# ESP32-S31 register map
Vendor: ESPRESSIF SYSTEMS (SHANGHAI) CO., LTD.; Series: ESP32 S-Series; File version: 1
CPU: RV32IMAFC r0p0, little endian, no MPU, FPU, 0 interrupt priority bits
Address unit: 32 bits
Registers are 32-bit, read-write, reset 0x0 unless marked. A register's access mark holds for its fields unless they carry their own. Offsets are from the block's base; [hi:lo] are bit positions; {n}, {i} and the like mark numbered series; <NAME> marks a mode.

## USB_OTG_HS (part 3 of 5) — USB_OTG_HS Peripheral
Base 0x20300000
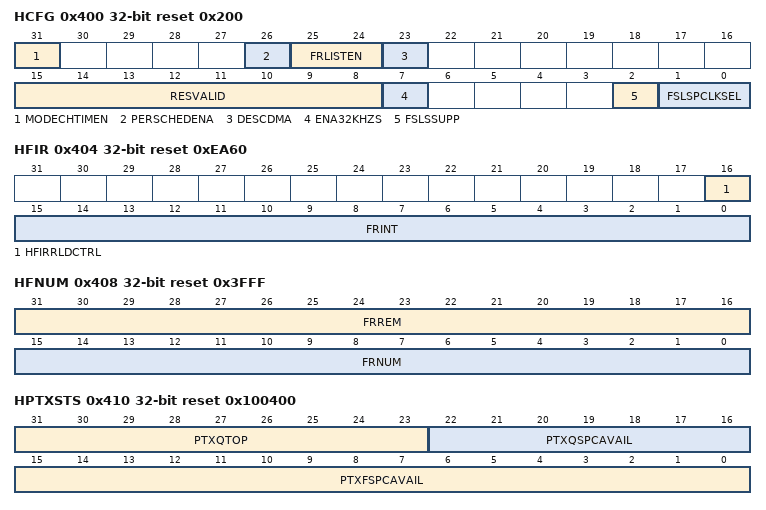
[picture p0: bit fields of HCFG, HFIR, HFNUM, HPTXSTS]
0x400 HCFG reset 0x200 — This register is used to configure the controller in Host mode.
  [31] MODECHTIMEN — Mode Change Ready Timer Enable (ModeChTimEn) This bit is used to enable/disable the Host core to wait 200 PHY clock cycles at the end of Resume to change the opmode signal to the PHY to 00 after Suspend or LPM. - 1'b0 : The Host core waits for either 200 PHY clock cycles or a linestate of SE0 at the end of resume to the change the opmode from 2'b10 to 2'b00 - 1'b1 : The Host core waits only for a linestate of SE0 at the end of resume to change the opmode from 2'b10 to 2'b00.
  [26] PERSCHEDENA — Enable Periodic Scheduling (PerSchedEna): Applicable in host DDMA mode only. Enables periodic scheduling within the core. Initially, the bit is reset. The core does not process any periodic channels. As soon as this bit is set, the core gets ready to start scheduling periodic channels and sets HCFG.PerSchedStat. The setting of HCFG.PerSchedStat indicates the core has enabled periodic scheduling. Once HCFG.PerSchedEna is set, the application is not supposed to again reset the bit unless HCFG.PerSchedStat is set. As soon as this bit is reset, the core gets ready to stop scheduling periodic channels and resets HCFG.PerSchedStat.
  [25:24] FRLISTEN — Frame List Entries(FrListEn) The value in the register specifies the number of entries in the Frame list. This field is valid only in Scatter/Gather DMA mode. - 2'b00: 8 Entries - 2'b01: 16 Entries - 2'b10: 32 Entries - 2'b11: 64 Entries
  [23] DESCDMA — Enable Scatter/gather DMA in Host mode (DescDMA) When the Scatter/Gather DMA option selected during configuration of the RTL, the application can set this bit during initialization to enable the Scatter/Gather DMA operation. Note: This bit must be modified only once after a reset. The following combinations are available for programming: - GAHBCFG.DMAEn=0,HCFG.DescDMA=0 => Slave mode - GAHBCFG.DMAEn=0,HCFG.DescDMA=1 => Invalid - GAHBCFG.DMAEn=1,HCFG.DescDMA=0 => Buffered DMA mode - GAHBCFG.DMAEn=1,HCFG.DescDMA=1 => Scatter/Gather DMA mode
  [15:8] RESVALID — Resume Validation Period (ResValid) This field is effective only when HCFG.Ena32KHzS is set. It controls the resume period when the core resumes from suspend. The core counts for 'ResValid' number of clock cycles to detect a valid resume when this is set.
  [7] ENA32KHZS — Enable 32 KHz Suspend mode (Ena32KHzS) This bit can be set only in FS PHY interface is selected. Else, this bit needs to be set to zero. When FS PHY interface is chosen and this bit is set, the core expects that the PHY clock during Suspend is switched from 48 MHz to 32 KHz.
  [2] FSLSSUPP — FS- and LS-Only Support (FSLSSupp) The application uses this bit to control the core's enumeration speed. Using this bit, the application can make the core enumerate as a FS host, even If the connected device supports HS traffic. Do not make changes to this field after initial programming. - 1'b0: HS/FS/LS, based on the maximum speed supported by the connected device - 1'b1: FS/LS-only, even If the connected device can support HS
  [1:0] FSLSPCLKSEL — FS/LS PHY Clock Select (FSLSPclkSel) When the core is in FS Host mode - 2'b00: PHY clock is running at 30/60 MHz - 2'b01: PHY clock is running at 48 MHz - Others: Reserved When the core is in LS Host mode - 2'b00: PHY clock is running at 30/60 MHz. When the UTMI+/ULPI PHY Low Power mode is not selected, use 30/60 MHz. - 2'b01: PHY clock is running at 48 MHz. When the UTMI+ PHY Low Power mode is selected, use 48MHz If the PHY supplies a 48 MHz clock during LS mode. - 2'b10: PHY clock is running at 6 MHz. In USB 1.1 FS mode, use 6 MHz when the UTMI+ PHY Low Power mode is selected and the PHY supplies a 6 MHz clock during LS mode. If you select a 6 MHz clock during LS mode, you must do a soft reset. - 2'b11: Reserved Notes: - When Core in FS mode, the internal and external clocks have the same frequency. - When Core in LS mode, -- If FSLSPclkSel = 2'b00: Internal and external clocks have the same frequency -- If FSLSPclkSel = 2'b10: Internal clock is the divided by eight version of external 48 MHz clock
0x404 HFIR reset 0xEA60 — This register is used to control the interval between two consecutive SOFs.
  [16] HFIRRLDCTRL — Reload Control (HFIRRldCtrl) This bit allows dynamic reloading of the HFIR register during run time. - 1'b0 : The HFIR cannot be reloaded dynamically - 1'b1: the HFIR can be dynamically reloaded during runtime. This bit needs to be programmed during initial configuration and its value must not be changed during runtime.
  [15:0] FRINT — Frame Interval (FrInt) The value that the application programs to this field specifies the interval between two consecutive SOFs (FS) or micro- SOFs (HS) or Keep-Alive tokens (HS). This field contains the number of PHY clocks that constitute the required frame interval. The Default value set in this field is for FS operation when the PHY clock frequency is 60 MHz. The application can write a value to this register only after the Port Enable bit of the Host Port Control and Status register (HPRT.PrtEnaPort) has been Set. If no value is programmed, the core calculates the value based on the PHY clock specified in the FS/LS PHY Clock Select field of the Host Configuration register (HCFG.FSLSPclkSel). Do not change the value of this field after the initial configuration. - 125 us * (PHY clock frequency for HS) - 1 ms * (PHY clock frequency for FS/LS)
0x408 HFNUM ro reset 0x3FFF — This register indicates the current frame number. It also indicates the time remaining (in terms of the number of PHY clocks) in the current (micro)frame. Note: Read the reset value of this register only after the following conditions: - If IDDIG_FILTER is disabled, read only when the PHY clock is stable. - If IDDIG_FILTER is enabled, read only after the filter timer expires.
  [31:16] FRREM — Frame Time Remaining (FrRem) Indicates the amount of time remaining in the current microframe (HS) or Frame (FS/LS), in terms of PHY clocks. This field decrements on each PHY clock. When it reaches zero, this field is reloaded with the value in the Frame Interval register and a new SOF is transmitted on the USB.
  [15:0] FRNUM — Frame Number (FrNum) This field increments when a new SOF is transmitted on the USB, and is reset to 0 when it reaches 16'h3FFF.
0x410 HPTXSTS ro reset 0x100400 — This register contains information about the Periodic Transmit Queue in the Host controller.
  [31:23] PTXQTOP — Top of the Periodic Transmit Request Queue (PTxQTop) This indicates the Entry in the Periodic Tx Request Queue that is currently being processed by the MAC. This register is used for debugging. - Bit [31]: Odd/Even (micro)Frame -- 1'b0: send in even (micro)Frame -- 1'b1: send in odd (micro)Frame - Bits [30:27]: Channel/endpoint number - Bits [26:25]: Type -- 2'b00: IN/OUT -- 2'b01: Zero-length packet -- 2'b10: CSPLIT -- 2'b11: Disable channel command - Bit [24]: Last Periodic Entry for the selected periodic channel/endpoint - Bit [23]: Terminate (last Entry for the selected channel/endpoint)
  [22:16] PTXQSPCAVAIL — Periodic Transmit Request Queue Space Available (PTxQSpcAvail) Indicates the number of free locations available to be written in the Periodic Transmit Request Queue. This queue holds both IN and OUT requests. - 7'h0: Periodic Transmit Request Queue is full - 7'h1: 1 location available - 7'h2: 2 locations available - n: n locations available (0 <= n <= 16) - Others: Reserved
  [15:0] PTXFSPCAVAIL — Periodic Transmit Data FIFO Space Available (PTxFSpcAvail) Indicates the number of free locations available to be written to in the Periodic TxFIFO. Values are in terms of 32-bit words - 16'h0 : Periodic TxFIFO is full - 16'h1 : 1 word available - 16'h2 : 2 words available - 16'hn : n words available (where 0 n 32,768) - 16'h8000 : 32,768 words - Others : Reserved
0x414 HAINT ro — When a significant event occurs on a channel, the Host All Channels Interrupt register interrupts the application using the Host Channels Interrupt bit of the Core Interrupt register (GINTSTS.HChInt). This is shown in the Interrupt Hierarchy figure in the databook. There is one interrupt bit per channel, up to a maximum of 16 bits. Bits in this register are set and cleared when the application sets and clears bits in the corresponding Host Channel-n Interrupt register.
  [15:0] HAINT — Channel Interrupt for channel no.
0x418 HAINTMSK — The Host All Channel Interrupt Mask register works with the Host All Channel Interrupt register to interrupt the application when an event occurs on a channel. There is one interrupt mask bit per channel, up to a maximum of 16 bits.
  [15:0] HAINTMSK — Channel Interrupt Mask (HAINTMsk) One bit per channel: Bit 0 for channel 0, bit 15 for channel 15
0x41C HFLBAddr — This register is present only in case of Scatter/Gather DMA. It is implemented as flops. This register holds the starting address of the Frame list information.
  [31:0] HFLBADDR_HFLBADDR — The starting address of the Frame list. This register is used only for Isochronous and Interrupt Channels.
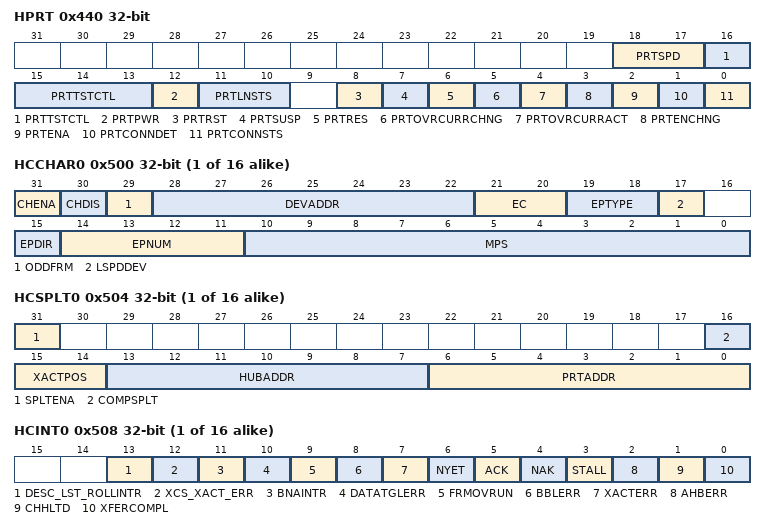
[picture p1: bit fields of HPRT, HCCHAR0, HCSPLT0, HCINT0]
0x440 HPRT access per field — This register is available only in Host mode. Currently, the OTG Host supports only one port. A single register holds USB port-related information such as USB reset, enable, suspend, resume, connect status, and test mode for each port. It is shown in the Interrupt Hierarchy figure in the databook. The R_SS_WC bits in this register can trigger an interrupt to the application through the Host Port Interrupt bit of the Core Interrupt register (GINTSTS.PrtInt). On a Port Interrupt, the application must read this register and clear the bit that caused the interrupt. For the R_SS_WC bits, the application must write a 1 to the bit to clear the interrupt.
  [18:17] PRTSPD ro — Port Speed (PrtSpd) Indicates the speed of the device attached to this port. - 2'b00: High speed - 2'b01: Full speed - 2'b10: Low speed - 2'b11: Reserved
  [16:13] PRTTSTCTL rw — Port Test Control (PrtTstCtl) The application writes a nonzero value to this field to put the port into a Test mode, and the corresponding pattern is signaled on the port. - 4'b0000: Test mode disabled - 4'b0001: Test_J mode - 4'b0010: Test_K mode - 4'b0011: Test_SE0_NAK mode - 4'b0100: Test_Packet mode - 4'b0101: Test_Force_Enable - Others: Reserved To move the DWC_otg controller to test mode, you must set this field. Complete the following steps to move the DWC_otg core to test mode: - 1. Power on the core. - 2. Load the DWC_otg driver. - 3. Connect an HS device and enumerate to HS mode. - 4. Access the HPRT register to send test packets. - 5. Remove the device and connect to fixture (OPT) port. The DWC_otg host core continues sending out test packets. - 6. Test the eye diagram.
  [12] PRTPWR rw — Port Power (PrtPwr) The application uses this field to control power to this port (write 1'b1 to set to 1'b1 and write 1'b0 to set to 1'b0), and the core can clear this bit on an over current condition. - 1'b0: Power off - 1'b1: Power on Note: This bit is interface independent. The application needs to program this bit for all interfaces as described in the host programming flow in the Programming Guide.
  [11:10] PRTLNSTS ro — Port Line Status (PrtLnSts) Indicates the current logic level USB data lines - Bit [10]: Logic level of D+ - Bit [11]: Logic level of D-
  [8] PRTRST rw — Port Reset (PrtRst) When the application sets this bit, a reset sequence is started on this port. The application must time the reset period and clear this bit after the reset sequence is complete. - 1'b0: Port not in reset - 1'b1: Port in reset The application must leave this bit set for at least a minimum duration mentioned below to start a reset on the port. The application can leave it set for another 10 ms in addition to the required minimum duration, before clearing the bit, even though there is no maximum limit Set by the USB standard.This bit is cleared by the core even if there is no device connected to the Host. - High speed: 50 ms - Full speed/Low speed: 10 ms
  [7] PRTSUSP rw — Port Suspend (PrtSusp) The application sets this bit to put this port in Suspend mode. The core only stops sending SOFs when this is Set. To stop the PHY clock, the application must Set the Port Clock Stop bit, which asserts the suspend input pin of the PHY. The read value of this bit reflects the current suspend status of the port. This bit is cleared by the core after a remote wakeup signal is detected or the application sets the Port Reset bit or Port Resume bit in this register or the Resume/Remote Wakeup Detected Interrupt bit or Disconnect Detected Interrupt bit in the Core Interrupt register (GINTSTS.WkUpInt or GINTSTS.DisconnInt, respectively).This bit is cleared by the core even if there is no device connected to the Host. - 1'b0: Port not in Suspend mode - 1'b1: Port in Suspend mode
  [6] PRTRES rw — Port Resume (PrtRes) The application sets this bit to drive resume signaling on the port. The core continues to drive the resume signal until the application clears this bit. If the core detects a USB remote wakeup sequence, as indicated by the Port Resume/Remote Wakeup Detected Interrupt bit of the Core Interrupt register (GINTSTS.WkUpInt), the core starts driving resume signaling without application intervention and clears this bit when it detects a disconnect condition. The read value of this bit indicates whether the core is currently driving resume signaling. - 1'b0: No resume driven - 1'b1: Resume driven When LPM is enabled, In L1 state the behavior of this bit is as follows: The application sets this bit to drive resume signaling on the port. The core continues to drive the resume signal until a pre-determined time specified in GLPMCFG.HIRD_Thres[3:0] field. If the core detects a USB remote wakeup sequence, as indicated by the Port L1Resume/Remote L1Wakeup Detected Interrupt bit of the Core Interrupt register (GINTSTS.L1WkUpInt), the core starts driving resume signaling without application intervention and clears this bit at the end of resume.This bit can be set by both core or application and also cleared by core or application. This bit is cleared by the core even if there is no device connected to the Host.
  [5] PRTOVRCURRCHNG rw — Port Overcurrent Change (PrtOvrCurrChng) The core sets this bit when the status of the Port Overcurrent Active bit (bit 4) in this register changes.This bit can be set only by the core and the application must write 1 to clear it
  [4] PRTOVRCURRACT ro — Port Overcurrent Active (PrtOvrCurrAct) Indicates the overcurrent condition of the port. - 1'b0: No overcurrent condition - 1'b1: Overcurrent condition
  [3] PRTENCHNG rw — Port Enable/Disable Change (PrtEnChng) The core sets this bit when the status of the Port Enable bit [2] of this register changes.This bit can be set only by the core and the application must write 1 to clear it.
  [2] PRTENA rw — Port Enable (PrtEna) A port is enabled only by the core after a reset sequence, and is disabled by an overcurrent condition, a disconnect condition, or by the application clearing this bit. The application cannot Set this bit by a register write. It can only clear it to disable the port by writing 1. This bit does not trigger any interrupt to the application. - 1'b0: Port disabled - 1'b1: Port enabled
  [1] PRTCONNDET rw — Port Connect Detected (PrtConnDet) The core sets this bit when a device connection is detected to trigger an interrupt to the application using the Host Port Interrupt bit of the Core Interrupt register (GINTSTS.PrtInt).This bit can be set only by the core and the application must write 1 to clear it.The application must write a 1 to this bit to clear the interrupt.
  [0] PRTCONNSTS ro — Port Connect Status (PrtConnSts) - 0: No device is attached to the port. - 1: A device is attached to the port.
{0x500+0x20*i} HCCHAR{i} (i=0..15) — This register contains the characteristics of the Host Channel.
  [31] CHENA — Channel Enable (ChEna) When Scatter/Gather mode is enabled - 1'b0: Indicates that the descriptor structure is not yet ready. - 1'b1: Indicates that the descriptor structure and data buffer with data is setup and this channel can access the descriptor. When Scatter/Gather mode is disabled This field is set by the application and cleared by the OTG host. - 1'b0: Channel disabled - 1'b1: Channel enabled
  [30] CHDIS — Channel Disable (ChDis) The application sets this bit to stop transmitting/receiving data on a channel, even before the transfer for that channel is complete. The application must wait for the Channel Disabled interrupt before treating the channel as disabled.
  [29] ODDFRM — Odd Frame (OddFrm) This field is set (reset) by the application to indicate that the OTG host must perform a transfer in an odd (micro)Frame. This field is applicable for only periodic (isochronous and interrupt) transactions. - 1'b0: Even (micro)Frame - 1'b1: Odd (micro)Frame
  [28:22] DEVADDR — Device Address (DevAddr) This field selects the specific device serving as the data source or sink.
  [21:20] EC — Multi Count (MC) / Error Count (EC) When the Split Enable bit of the Host Channel-n Split Control register (HCSPLTn.SpltEna) is reset (1'b0), this field indicates to the host the number of transactions that must be executed per microframe for this periodic endpoint. For non periodic transfers, this field is used only in DMA mode, and specifies the number packets to be fetched for this channel before the internal DMA engine changes arbitration. - 2'b00: Reserved This field yields undefined results. - 2'b01: 1 transaction - 2'b10: 2 transactions to be issued for this endpoint per microframe - 2'b11: 3 transactions to be issued for this endpoint per microframe When HCSPLTn.SpltEna is Set (1'b1), this field indicates the number of immediate retries to be performed for a periodic split transactions on transaction errors. This field must be Set to at least 2'b01.
  [19:18] EPTYPE — Endpoint Type (EPType) Indicates the transfer type selected. - 2'b00: Control - 2'b01: Isochronous - 2'b10: Bulk - 2'b11: Interrupt
  [17] LSPDDEV — Low-Speed Device (LSpdDev) This field is Set by the application to indicate that this channel is communicating to a low-speed device. The application must program this bit when a low speed device is connected to the host through an FS HUB. The DWC_otg Host core uses this field to drive the XCVR_SELECT signal to 2'b11 while communicating to the LS Device through the FS hub. Note: In a peer to peer setup, the DWC_otg Host core ignores this bit even if it is set by the application software.
  [15] EPDIR — Endpoint Direction (EPDir) Indicates whether the transaction is IN or OUT. - 1'b0: OUT - 1'b1: IN
  [14:11] EPNUM — Endpoint Number (EPNum) Indicates the endpoint number on the device serving as the data source or sink.
  [10:0] MPS — Maximum Packet Size (MPS) Indicates the maximum packet size of the associated endpoint.
{0x504+0x20*i} HCSPLT{i} (i=0..15) — This register contains the Split characteristics of the Host Channel.
  [31] SPLTENA — Split Enable (SpltEna) The application sets this field to indicate that this channel is enabled to perform split transactions.
  [16] COMPSPLT — Do Complete Split (CompSplt) The application sets this field to request the OTG host to perform a complete split transaction.
  [15:14] XACTPOS — Transaction Position (XactPos) This field is used to determine whether to send all, first, middle, or last payloads with each OUT transaction. - 2'b11: All. This is the entire data payload is of this transaction (which is less than or equal to 188 bytes). - 2'b10: Begin. This is the first data payload of this transaction (which is larger than 188 bytes). - 2'b00: Mid. This is the middle payload of this transaction (which is larger than 188 bytes). - 2'b01: End. This is the last payload of this transaction (which is larger than 188 bytes).
  [13:7] HUBADDR — Hub Address (HubAddr) This field holds the device address of the transaction translator's hub.
  [6:0] PRTADDR — Port Address (PrtAddr) This field is the port number of the recipient transaction translator.
{0x508+0x20*i} HCINT{i} (i=0..15) — This register indicates the status of a channel with respect to USB- and AHB-related events. It is shown in the Interrupt Hierarchy figure in the databook. The application must read this register when the Host Channels Interrupt bit of the Core Interrupt register (GINTSTS.HChInt) is set. Before the application can read this register, it must first read the Host All Channels Interrupt (HAINT) register to get the exact channel number for the Host Channel-n Interrupt register. The application must clear the appropriate bit in this register to clear the corresponding bits in the HAINT and GINTSTS registers.
  [13] DESC_LST_ROLLINTR — Descriptor rollover interrupt (DESC_LST_ROLLIntr) This bit is valid only when Scatter/Gather DMA mode is enabled. The core sets this bit when the corresponding channel's descriptor list rolls over. For non Scatter/Gather DMA mode, this bit is reserved.
  [12] XCS_XACT_ERR — Excessive Transaction Error (XCS_XACT_ERR) This bit is valid only when Scatter/Gather DMA mode is enabled. The core sets this bit when 3 consecutive transaction errors occurred on the USB bus. XCS_XACT_ERR is not generated for Isochronous channels. For non Scatter/Gather DMA mode, this bit is reserved.
  [11] BNAINTR — BNA (Buffer Not Available) Interrupt (BNAIntr) This bit is valid only when Scatter/Gather DMA mode is enabled. The core generates this interrupt when the descriptor accessed is not ready for the Core to process. BNA is not generated for Isochronous channels. For non Scatter/Gather DMA mode, this bit is reserved.
  [10] DATATGLERR — Data Toggle Error (DataTglErr).This bit can be set only by the core and the application must write 1 to clear it.In Scatter/Gather DMA mode, the interrupt due to this bit is masked in the core.
  [9] FRMOVRUN — Frame Overrun (FrmOvrun). In Scatter/Gather DMA mode, the interrupt due to this bit is masked in the core. This bit can be set only by the core and the application must write 1 to clear it.
  [8] BBLERR — Babble Error (BblErr) In Scatter/Gather DMA mode, the interrupt due to this bit is masked in the core. This bit can be set only by the core and the application must write 1 to clear it.
  [7] XACTERR — Transaction Error (XactErr) Indicates one of the following errors occurred on the USB. - CRC check failure - Timeout - Bit stuff error - False EOP In Scatter/Gather DMA mode, the interrupt due to this bit is masked in the core.This bit can be set only by the core and the application must write 1 to clear it.
  [6] NYET — NYET Response Received Interrupt (NYET) In Scatter/Gather DMA mode, the interrupt due to this bit is masked in the core.This bit can be set only by the core and the application must write 1 to clear it.
  [5] ACK — ACK Response Received/Transmitted Interrupt (ACK) In Scatter/Gather DMA mode, the interrupt due to this bit is masked in the core.This bit can be set only by the core and the application must write 1 to clear it.
  [4] NAK — NAK Response Received Interrupt (NAK) In Scatter/Gather DMA mode, the interrupt due to this bit is masked in the core.This bit can be set only by the core and the application must write 1 to clear it.
  [3] STALL — STALL Response Received Interrupt (STALL) In Scatter/Gather DMA mode, the interrupt due to this bit is masked in the core.This bit can be set only by the core and the application must write 1 to clear it.
  [2] AHBERR — AHB Error (AHBErr) This is generated only in Internal DMA mode when there is an AHB error during AHB read/write. The application can read the corresponding channel's DMA address register to get the error address. For details, see AHB Error Handling in the Programming Guide.
  [1] CHHLTD — Channel Halted (ChHltd) In non Scatter/Gather DMA mode, it indicates the transfer completed abnormally either because of any USB transaction error or in response to disable request by the application or because of a completed transfer. In Scatter/gather DMA mode, this indicates that transfer completed due to any of the following - EOL being set in descriptor - AHB error - Excessive transaction errors - Babble - Stall
  [0] XFERCOMPL — Transfer Completed (XferCompl) Transfer completed normally without any errors.This bit can be set only by the core and the application must write 1 to clear it. - For Scatter/Gather DMA mode, it indicates that current descriptor processing got completed with IOC bit set in its descriptor. - In non Scatter/Gather DMA mode, it indicates that Transfer completed normally without any errors.
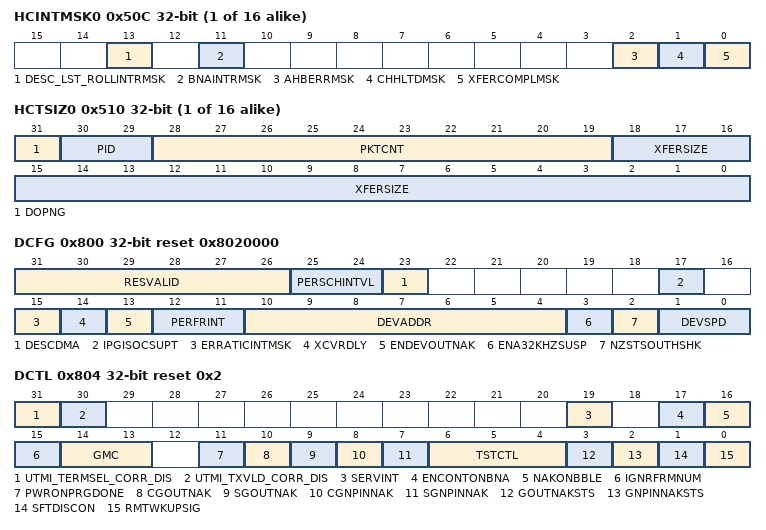
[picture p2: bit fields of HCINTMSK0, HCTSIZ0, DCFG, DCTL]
{0x50C+0x20*i} HCINTMSK{i} (i=0..15) — This register reflects the mask for each channel status described in the previous section.
  [13] DESC_LST_ROLLINTRMSK — Descriptor List rollover interrupt Mask register(DESC_LST_ROLLIntrMsk) This bit is valid only when Scatter/Gather DMA mode is enabled.
  [11] BNAINTRMSK — BNA (Buffer Not Available) Interrupt mask register (BNAIntrMsk) This bit is valid only when Scatter/Gather DMA mode is enabled.
  [2] AHBERRMSK — AHB Error Mask (AHBErrMsk) In scatter/gather DMA mode for host, interrupts are not generated due to the corresponding bits set in HCINTn.
  [1] CHHLTDMSK — Channel Halted Mask (ChHltdMsk)
  [0] XFERCOMPLMSK — Transfer Completed Mask (XferComplMsk)
{0x510+0x20*i} HCTSIZ{i} (i=0..15) — This register reflects the transfer size for the Host Channel.
  [31] DOPNG — Do Ping (DoPng) This bit is used only for OUT transfers. Setting this field to 1 directs the host to do PING protocol. Note: Do not set this bit for IN transfers. If this bit is set for IN transfers it disables the channel.
  [30:29] PID — PID (Pid) The application programs this field with the type of PID to use for the initial transaction. The host maintains this field for the rest of the transfer. - 2'b00: DATA0 - 2'b01: DATA2 - 2'b10: DATA1 - 2'b11: MDATA (non-control)/SETUP (control)
  [28:19] PKTCNT — Non-Scatter/Gather DMA Mode: Packet Count (PktCnt) This field is programmed by the application with the expected number of packets to be transmitted (OUT) or received (IN). The host decrements this count on every successful transmission or reception of an OUT/IN packet. Once this count reaches zero, the application is interrupted to indicate normal completion. The width of this counter is specified as Width of Packet Counters during coreConsultant configuration (parameter OTG_PACKET_COUNT_WIDTH). Scatter/Gather DMA Mode: [28:19]: Reserved
  [18:0] XFERSIZE — Non-Scatter/Gather DMA Mode: Transfer Size (XferSize) For an OUT, this field is the number of data bytes the host sends during the transfer. For an IN, this field is the buffer size that the application has Reserved for the transfer. The application is expected to program this field as an integer multiple of the maximum packet size for IN transactions (periodic and non-periodic). The width of this counter is specified as Width of Transfer Size Counters during coreConsultant configuration (parameter OTG_TRANS_COUNT_WIDTH). Scatter/Gather DMA Mode: [18:16]: Reserved [15:8]: NTD (Number of Transfer Descriptors) (Non Isochronous) This value is in terms of number of descriptors. Maximum number of descriptor that can be present in the list is 64. The values can be from 0 to 63. - 0: 1 descriptor - 63: 64 descriptors This field indicates the total number of descriptors present in that list. The core wraps around after servicing NTD number of descriptors for that list. (Isochronous) This field indicates the number of descriptors present in that list microframe. The possible values for FS are - 1: 2 descriptors - 3: 4 descriptors - 7: 8 descriptors - 15: 16 descriptors - 31: 32 descriptors - 63: 64 descriptors The possible values for HS are - 7: 8 descriptors - 15: 16 descriptors - 31: 32 descriptors - 63: 64 descriptors - 127: 128 descriptors - 255: 256 descriptors [7:0]: SCHED_INFO (Schedule information) Every bit in this 8 bit register indicates scheduling for that microframe. Bit 0 indicates scheduling for 1st microframe and bit 7 indicates scheduling for 8th microframe in that frame. A value of 8'b11111111 indicates that the corresponding interrupt channel is scheduled to issue a token every microframe in that frame. A value of 8'b10101010 indicates that the corresponding interrupt channel is scheduled to issue a token every alternate microframe starting with second microframe. Note that this field is applicable only for periodic (Isochronous and Interrupt) channels.
{0x514+0x20*i} HCDMA{i} (i=0..15) — This register is used by the OTG host in the internal DMA mode to maintain the current buffer pointer for IN/OUT transactions. The starting DMA address must be DWORD-aligned.
  [31:0] DMAADDR — In Buffer DMA Mode: [31:0]: DMA Address (DMAAddr) This field holds the start address in the external memory from which the data for the endpoint must be fetched or to which it must be stored. This register is incremented on every AHB transaction. Reset: X if not programmed as the register is in SPRAM. In Scatter-Gather DMA (DescDMA) Mode for Non-Isochronous: [31:9]: DMA Address (DMAAddr) The start address must be 512-bytes aligned. This field holds the start address of the 512 bytes page. The first descriptor in the list must be located in this address. The first descriptor may be or may not be ready. The core starts processing the list from the CTD value. [8:3]: Current Transfer Desc(CTD) This value is in terms of number of descriptors. The values can be from 0 to 63. - 0 - 1 descriptor. - 63 - 64 descriptors. This field indicates the current descriptor processed in the list. This field is updated both by application and the core. For example, if the application enables the channel after programming CTD=5, then the core starts processing the sixth descriptor. The address is obtained by adding a value of (8bytes*5=) 40(decimal) to DMAAddr. Reset: 6'h0 [2:0]: Reserved In Scatter-Gather DMA (DescDMA) Mode for Isochronous: [31:N]: DMA Address (DMAAddr) The start address must be 512-bytes aligned. This field holds the address of the 2*(nTD+1) bytes of locations in which the isochronous descriptors are present where N is based on nTD as follows: - [31:N]: Base Address - [N-1:3]: Offset - [2:0]: 000 For HS ISOC, if nTD is, - 7, N=6 - 15, N=7 - 31, N=8 - 63, N=9 - 127, N=10 - 255, N=11 For FS ISOC, if nTD is, - 1, N=4 - 3, N=5 - 7, N=6 - 15, N=7 - 31, N=8 - 63, N=9 [N-1:3]: Current Transfer Desc(CTD) CTD for isochronous is based on the current frame/(micro)frame value. Need to be set to zero by application. Reset: (N+1:3)'h0 [2:0]: Reserved
{0x51C+0x20*i} HCDMAB{i} ro (i=0..15) — This register is present only in case of Scatter/Gather DMA. It is implemented in RAM instead of flop-based implementation. This register holds the current buffer address.
  [31:0] HCDMAB — Holds the current buffer address. This register is updated as and when the data transfer for the corresponding end point is in progress. This register is present only in Scatter/Gather DMA mode. Otherwise this field is reserved.
0x800 DCFG reset 0x8020000 — This register configures the core in Device mode after power-on or after certain control commands or enumeration. Do not make changes to this register after initial programming.
  [31:26] RESVALID — Resume Validation Period (ResValid) This field is effective only when DCFG.Ena32KHzSusp is set. It controls the resume period when the core resumes from suspend. The core counts for ResValid number of clock cycles to detect a valid resume when this bit is set
  [25:24] PERSCHINTVL — Periodic Scheduling Interval (PerSchIntvl) PerSchIntvl must be programmed for Scatter/Gather DMA mode. This field specifies the amount of time the Internal DMA engine must allocate for fetching periodic IN endpoint data. Based on the number of periodic endpoints, this value must be specified as 25,50 or 75% of (micro)Frame. - When any periodic endpoints are active, the internal DMA engine allocates the specified amount of time in fetching periodic IN endpoint data . - When no periodic endpoints are active, Then the internal DMA engine services non-periodic endpoints, ignoring this field. - After the specified time within a (micro)Frame, the DMA switches to fetching for non-periodic endpoints. -- 2'b00: 25% of (micro)Frame. -- 2'b01: 50% of (micro)Frame. -- 2'b10: 75% of (micro)Frame. -- 2'b11: Reserved. Reset: 2'b00
  [23] DESCDMA — Enable Scatter/gather DMA in device mode (DescDMA). When the Scatter/Gather DMA option selected during configuration of the RTL, the application can Set this bit during initialization to enable the Scatter/Gather DMA operation. Note: This bit must be modified only once after a reset. The following combinations are available for programming: - GAHBCFG.DMAEn=0,DCFG.DescDMA=0 => Slave mode - GAHBCFG.DMAEn=0,DCFG.DescDMA=1 => Invalid - GAHBCFG.DMAEn=1,DCFG.DescDMA=0 => Buffered DMA mode - GAHBCFG.DMAEn=1,DCFG.DescDMA=1 => Scatter/Gather DMA mode
  [17] IPGISOCSUPT — Worst-Case Inter-Packet Gap ISOC OUT Support (ipgisocSupt) This bit indicates that the controller supports the worst-case scenario of Rx followed by Rx Inter-Packet Gap (IPG) (32 bit times) as per the UTMI Specification for any token following an ISOC OUT token. Without this support, when any token follows an ISOC OUT token with the worst-case IPG, the controller does not detect the followed token. The worst-case IPG of the controller without this support depends on the AHB and PHY clock frequency.
  [15] ERRATICINTMSK — Erratic Error Interrupt Mask
  [14] XCVRDLY — XCVRDLY Enables or disables delay between xcvr_sel and txvalid during device chirp
  [13] ENDEVOUTNAK — Enable Device OUT NAK (EnDevOutNak) This bit enables setting NAK for Bulk OUT endpoints after the transfer is completed for Device mode Descriptor DMA - 1'b0 : The core does not set NAK after Bulk OUT transfer complete - 1'b1 : The core sets NAK after Bulk OUT transfer complete This bit is one time programmable after reset like any other DCFG register bits.
  [12:11] PERFRINT — Periodic Frame Interval (PerFrInt) Indicates the time within a (micro)Frame at which the application must be notified using the End Of Periodic Frame Interrupt. This can be used to determine If all the isochronous traffic for that (micro)Frame is complete. - 2'b00: 80% of the (micro)Frame interval - 2'b01: 85% of the (micro)Frame interval - 2'b10: 90% of the (micro)Frame interval - 2'b11: 95% of the (micro)Frame interval
  [10:4] DEVADDR — Device Address (DevAddr) The application must program this field after every SetAddress control command.
  [3] ENA32KHZSUSP — Enable 32 KHz Suspend mode (Ena32KHzSusp) This bit can be set only if FS PHY interface is selected. Otherwise, this bit needs to be set to zero. If FS PHY interface is chosen and this bit is set, the PHY clock during Suspend must be switched from 48 MHz to 32 KHz.
  [2] NZSTSOUTHSHK — Non-Zero-Length Status OUT Handshake (NZStsOUTHShk) The application can use this field to select the handshake the core sends on receiving a nonzero-length data packet during the OUT transaction of a control transfer's Status stage. - 1'b1: Send a STALL handshake on a nonzero-length status OUT transaction and do not send the received OUT packet to the application. - 1'b0: Send the received OUT packet to the application (zerolength or nonzero-length) and send a handshake based on the NAK and STALL bits for the endpoint in the Device Endpoint Control register.
  [1:0] DEVSPD — Device Speed (DevSpd) Indicates the speed at which the application requires the core to enumerate, or the maximum speed the application can support. However, the actual bus speed is determined only after the connect sequence is completed, and is based on the speed of the USB host to which the core is connected.
0x804 DCTL access per field reset 0x2 — This register is used to control the characteristics of the Device controller.
  [31] UTMI_TERMSEL_CORR_DIS rw — Disable the correction of TermSel on UTMI Interface. When the application sets Soft disconnect (DCTL.SftDiscon=1'b1), the behavior of TermSel has been corrected to drive the valid combination of XcvrSel (FS_XCVR) and TermSel (FS_TERM). The application can set this register bit to 1'b1 to fall back to the original behavior of the Device controller driving XcvrSel (FS_XCVR) and TermSel (HS_TERM) when Soft disconnect is set (DCTL.SftDiscon=1'b1). - 1'b0: Valid Combination of XcvrSel and TermSel is driven by the Device Controller. When this bit is set to 1'b0, the Device controller drives TermSel to 1 upon assertion of Soft Disconnect which enables FS Termination. - 1'b1: Invalid Combination of XcvrSel and TermSel is driven by the Device Controller. When this bit is set to 1'b1, the Device controller drives TermSel to 0 upon assertion of Soft Disconnect which enables HS Termination. Note: The application must program this register during Device Initialization before USB Reset and this value cannot be changed afterwards.
  [30] UTMI_TXVLD_CORR_DIS rw — Disable the correction to OpMode/XcvrSel/TermSel on UTMI Interface. When Soft disconnect (DCTL.SftDiscon=1'b1) is set by the application, the Device controller immediately changes the Opmode to Non-Driving (2'b01), XcvrSel to FS_XCVR (2'b01) and TermSel to HS_TERM (1'b1). If the Device controller is disconnected (DCTL.SftDiscon=1'b1) while transmitting a packet or a chirp, then the Device controller immediately changes the Opmode to Non-Driving (2'b01) while TxValid being High (1'b1). Certain PHYs may not respond to the TxValid by interpreting the change in OpMode to Non-Driving. The behavior of OpMode, XcvrSel and TermSel have been corrected to handle Soft disconnect during transmission. The application can set this register bit to 1'b1 to fall back to the original behavior of OpMode, XcvrSel, TermSel when Soft disconnect is set during transmission. - 1'b0: Opmode, XcvrSel, TermSel are changed by the Device Controller after TxValid goes LOW (1'b0). When this bit is set to 1'b0, the Device controller changes Opmode, XcvrSel and TermSel when TxVlaid is low after assertion of Soft Disconnect. - 1'b1: Opmode, XcvrSel, TermSel are changed by the Device Controller immediately. When this bit is set to 1'b1, the Device controller changes Opmode, XcvrSel and TermSel immediately after assertion of Soft Disconnect. Note: The application must program this register during Device Initialization before USB Reset and this value cannot be changed afterwards.
  [19] SERVINT rw — Service Interval based scheduling for Isochronous IN Endpoints This field is used to enable service interval based scheduling feature for ISOC IN EPs. Note: This bit is applicable only in device mode and when Scatter/Gather DMA mode is used. This feature must not be enabled along with DCTL.IgnrFrmNum. Scatter/Gather DMA Mode (GAHBCFG.DMAEn=1,DCFG.DescDMA=1): When this bit is enabled, the frame number field in the ISOC IN descriptor structure is interpreted as the last frame of the service interval. In Scatter/Gather DMA mode, if this bit is enabled, the pending packets are flushed by the controller at the last frame of the service interval.
  [17] ENCONTONBNA rw — Enable Continue on BNA (EnContOnBNA) This bit enables the core to continue on BNA for Bulk OUT endpoints. With this feature enabled, when a Bulk OUT or INTR OUT endpoint receives a BNA interrupt the core starts processing the descriptor that caused the BNA interrupt after the endpoint re-enables the endpoint. - 1'b0: After receiving BNA interrupt,the core disables the endpoint. When the endpoint is re-enabled by the application, the core starts processing from the DOEPDMA descriptor. - 1'b1: After receiving BNA interrupt, the core disables the endpoint. When the endpoint is re-enabled by the application, the core starts processing from the descriptor that received the BNA interrupt. This bit is valid only when OTG_EN_DESC_DMA == 1'b1. It is a one-time programmable after reset bit like any other DCTL register bits.
  [16] NAKONBBLE rw — NAK on Babble Error (NakOnBble) Set NAK automatically on babble (NakOnBble). The core sets NAK automatically for the endpoint on which babble is received.
  [15] IGNRFRMNUM rw — Ignore Frame Number Feature for Isochronous Endpoints (IgnrFrmNum) This field is also used to control the Periodic Transfer Interrupt (PTI) feature. Note: Do not program IgnrFrmNum bit to 1'b1 when the core is operating in threshold mode. Slave Mode (GAHBCFG.DMAEn=0): This bit is not valid in Slave mode and must not be programmed to 1. Scatter/Gather DMA Mode (GAHBCFG.DMAEn=1,DCFG.DescDMA=1): Note: When Scatter/Gather DMA mode is enabled this feature is not applicable to High Speed, High bandwidth transfers. When this bit is enabled, there must be only one packet per descriptor. - 0: The core transmits the packets only in the frame number in which they are intended to be transmitted. - 1: The core ignores the frame number, sending packets immediately as the packets are ready. In Scatter/Gather DMA mode, if this bit is enabled, the packets are not flushed when a ISOC IN token is received for an elapsed frame. Non-Scatter/Gather DMA Mode, that is, Buffer DMA Mode (GAHBCFG.DMAEn=1,DCFG.DescDMA=0): When Scatter/Gather DMA mode is disabled, this field is used by the application to enable Periodic Transfer Interrupt (PTI) Mode. The application can program Periodic Endpoint transfers for multiple (micro)Frames. - 0: Periodic Transfer Interrupt feature is disabled, application needs to program transfers for periodic endpoints every (micro)Frame - 1: Periodic Transfer Interrupt feature is enabled, application can program transfers for multiple (micro)Frames for periodic endpoints. In the PTI mode, the application receives Transfer Complete Interrupt after transfers for multiple (micro)Frames are completed.
  [14:13] GMC rw — Global Multi Count (GMC) GMC must be programmed only once after initialization. Applicable only for Scatter/Gather DMA mode. This indicates the number of packets to be serviced for that end point before moving to the next end point. It is only for non-periodic endpoints. - 2'b00: Invalid. - 2'b01: 1 packet. - 2'b10: 2 packets. - 2'b11: 3 packets. The value of this field automatically changes to 2'h1 when DCFG.DescDMA is set to 1. When Scatter/Gather DMA mode is disabled, this field is reserved. and reads 2'b00.
  [11] PWRONPRGDONE rw — Power-On Programming Done (PWROnPrgDone) The application uses this bit to indicate that register programming is completed after a wake-up from Power Down mode.
  [10] CGOUTNAK rw — Clear Global OUT NAK (CGOUTNak) A write to this field clears the Global OUT NAK.
  [9] SGOUTNAK rw — Set Global OUT NAK (SGOUTNak) A write to this field sets the Global OUT NAK. The application uses this bit to send a NAK handshake on all OUT endpoints. The application must set the this bit only after making sure that the Global OUT NAK Effective bit in the Core Interrupt Register (GINTSTS.GOUTNakEff) is cleared.
  [8] CGNPINNAK rw — Clear Global Non-periodic IN NAK (CGNPInNak) A write to this field clears the Global Non-periodic IN NAK.
  [7] SGNPINNAK rw — Set Global Non-periodic IN NAK (SGNPInNak) A write to this field sets the Global Non-periodic IN NAK.The application uses this bit to send a NAK handshake on all non-periodic IN endpoints. The core can also Set this bit when a timeout condition is detected on a non-periodic endpoint in shared FIFO operation. The application must Set this bit only after making sure that the Global IN NAK Effective bit in the Core Interrupt Register (GINTSTS.GINNakEff) is cleared
  [6:4] TSTCTL rw — Test Control (TstCtl) - 3'b000: Test mode disabled - 3'b001: Test_J mode - 3'b010: Test_K mode - 3'b011: Test_SE0_NAK mode - 3'b100: Test_Packet mode - 3'b101: Test_Force_Enable - Others: Reserved
  [3] GOUTNAKSTS ro — Global OUT NAK Status (GOUTNakSts) - 1'b0: A handshake is sent based on the FIFO Status and the NAK and STALL bit settings. - 1'b1: No data is written to the RxFIFO, irrespective of space availability. Sends a NAK handshake on all packets, except on SETUP transactions. All isochronous OUT packets are dropped.
  [2] GNPINNAKSTS ro — Global Non-periodic IN NAK Status (GNPINNakSts) - 1'b0: A handshake is sent out based on the data availability in the transmit FIFO. - 1'b1: A NAK handshake is sent out on all non-periodic IN endpoints, irrespective of the data availability in the transmit FIFO.
  [1] SFTDISCON rw — Soft Disconnect (SftDiscon) The application uses this bit to signal the controller to do a soft disconnect. As long as this bit is set, the host does not see that the device is connected, and the device does not receive signals on the USB. The core stays in the disconnected state until the application clears this bit. - 1'b0: Normal operation. When this bit is cleared after a soft disconnect, the core drives the phy_opmode_o signal on the UTMI+ to 2'b00, which generates a device connect event to the USB host. When the device is reconnected, the USB host restarts device enumeration. - 1'b1: The core drives the phy_opmode_o signal on the UTMI+ to 2'b01, which generates a device disconnect event to the USB host. The following is the minimum duration under various conditions for which this bit must be set for the USB host to detect a device disconnect. To accommodate clock jitter, it is recommended that the application adds some extra delay to the specified minimum duration. For high speed, if the device state is, - Suspended, the minimum duration is 1ms + 2.5us - Idle, the minimum duration is 3ms + 2.5us - Not Idle or Suspended (performing transactions), the minimum duration 125 us For full speed/low speed, if the device state is, - Suspended, the minimum duration is 1ms + 2.5us - Idle, the minimum duration is 2.5us - Not Idle or Suspended (performing transactions), the minimum duration 125 us Note: - This bit can be also used for ULPI/FS Serial interfaces. - This bit is not impacted by a soft reset.
  [0] RMTWKUPSIG rw — Remote Wakeup Signaling (RmtWkUpSig) When the application sets this bit, the core initiates remote signaling to wake up the USB host. The application must Set this bit to instruct the core to exit the Suspend state. As specified in the USB 2.0 specification, the application must clear this bit 1-15 ms after setting it. If LPM is enabled and the core is in the L1 (Sleep) state, when the application sets this bit, the core initiates L1 remote signaling to wake up the USB host. The application must set this bit to instruct the core to exit the Sleep state. As specified in the LPM specification, the hardware automatically clears this bit 50 microseconds (TL1DevDrvResume) after being set by the application. The application must not set this bit when GLPMCFG bRemoteWake from the previous LPM transaction is zero.
